# ATSAMD20G16B device description
Architecture: CORTEX-M0PLUS; Family: SAMD; Series: SAMD20
Registers are 8-bit, read-write, reset 0x0 unless marked. A register's access mark holds for its fields unless they carry their own. Offsets are from the block's base; [hi:lo] are bit positions; lines under a group give offsets from that group; {n}, {i} and the like mark numbered series; 'fields as' and 'values as' point back to an identical list.

## PAC — Peripheral Access Controller
Instances: PAC0 0x40000000, PAC1 0x41000000, PAC2 0x42000000
0x00 WPCLR 32-bit (atomic clear) — Write Protection Clear
  [31:1] WP
0x04 WPSET 32-bit (atomic set) — Write Protection Set
  [31:1] WP

## PM — Power Manager
Instances: PM 0x40000400
0x00 CTRL — Control
0x01 SLEEP — Sleep Mode
  [1:0] IDLE — Idle Mode Configuration
    0=CPU (The CPU clock domain is stopped); 1=AHB (The CPU and AHB clock domains are stopped); 2=APB (The CPU, AHB and APB clock domains are stopped)
0x08 CPUSEL — CPU Clock Select
  [2:0] CPUDIV — CPU Prescaler Selection
    0=DIV1 (Divide by 1); 1=DIV2 (Divide by 2); 2=DIV4 (Divide by 4); 3=DIV8 (Divide by 8); 4=DIV16 (Divide by 16); 5=DIV32 (Divide by 32); 6=DIV64 (Divide by 64); 7=DIV128 (Divide by 128)
0x09 APBASEL — APBA Clock Select
  [2:0] APBADIV — APBA Prescaler Selection
    values as CPUSEL.CPUDIV
0x0A APBBSEL — APBB Clock Select
  [2:0] APBBDIV — APBB Prescaler Selection
    values as CPUSEL.CPUDIV
0x0B APBCSEL — APBC Clock Select
  [2:0] APBCDIV — APBC Prescaler Selection
    values as CPUSEL.CPUDIV
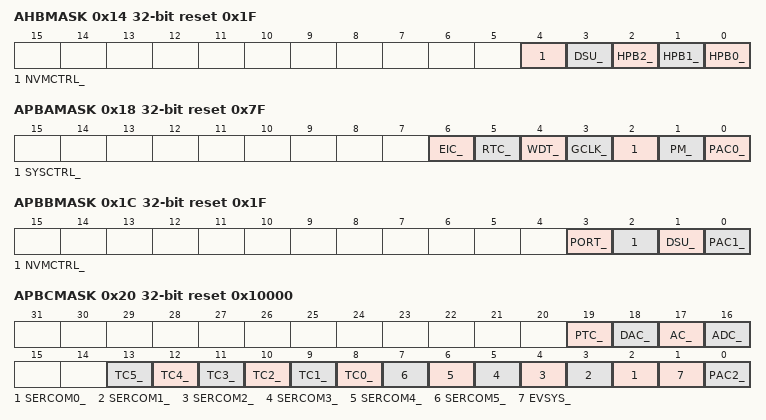
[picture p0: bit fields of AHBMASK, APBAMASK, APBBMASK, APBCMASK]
0x14 AHBMASK 32-bit reset 0x1F
  [4] NVMCTRL_ — NVMCTRL AHB Clock Mask
  [3] DSU_ — DSU AHB Clock Mask
  [2] HPB2_ — HPB2 AHB Clock Mask
  [1] HPB1_ — HPB1 AHB Clock Mask
  [0] HPB0_ — HPB0 AHB Clock Mask
0x18 APBAMASK 32-bit reset 0x7F
  [6] EIC_ — EIC APB Clock Enable
  [5] RTC_ — RTC APB Clock Enable
  [4] WDT_ — WDT APB Clock Enable
  [3] GCLK_ — GCLK APB Clock Enable
  [2] SYSCTRL_ — SYSCTRL APB Clock Enable
  [1] PM_ — PM APB Clock Enable
  [0] PAC0_ — PAC0 APB Clock Enable
0x1C APBBMASK 32-bit reset 0x1F
  [3] PORT_ — PORT APB Clock Enable
  [2] NVMCTRL_ — NVMCTRL APB Clock Enable
  [1] DSU_ — DSU APB Clock Enable
  [0] PAC1_ — PAC1 APB Clock Enable
0x20 APBCMASK 32-bit reset 0x10000
  [19] PTC_ — PTC APB Clock Enable
  [18] DAC_ — DAC APB Clock Enable
  [17] AC_ — AC APB Clock Enable
  [16] ADC_ — ADC APB Clock Enable
  [n+8] TC{n}_ (n=0..5) — TC{n} APB Clock Enable
  [n+2] SERCOM{n}_ (n=0..5) — SERCOM{n} APB Clock Enable
  [1] EVSYS_ — EVSYS APB Clock Enable
  [0] PAC2_ — PAC2 APB Clock Enable
0x34 INTENCLR (atomic clear) — Interrupt Enable Clear
  [0] CKRDY — Clock Ready Interrupt Enable
0x35 INTENSET (atomic set) — Interrupt Enable Set
  [0] CKRDY — Clock Ready Interrupt Enable
0x36 INTFLAG (atomic clear) — Interrupt Flag Status and Clear
  [0] CKRDY — Clock Ready
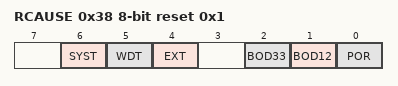
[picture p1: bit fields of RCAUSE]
0x38 RCAUSE ro reset 0x1 — Reset Cause
  [6] SYST — System Reset Request
  [5] WDT — Watchdog Reset
  [4] EXT — External Reset
  [2] BOD33 — Brown Out 33 Detector Reset
  [1] BOD12 — Brown Out 12 Detector Reset
  [0] POR — Power On Reset

## PORT — Port Module
Instances: PORT 0x41004400, PORT_IOBUS 0x60000000
{0x0+0x80*i} GROUP[{i}] (i=0..1) group
  0x00 DIR 32-bit — Data Direction
    [31:0] DIR — Port Data Direction
  0x04 DIRCLR 32-bit (atomic clear of DIR) — Data Direction Clear
    [31:0] DIRCLR — Port Data Direction Clear
  0x08 DIRSET 32-bit (atomic set of DIR) — Data Direction Set
    [31:0] DIRSET — Port Data Direction Set
  0x0C DIRTGL 32-bit (atomic toggle of DIR) — Data Direction Toggle
    [31:0] DIRTGL — Port Data Direction Toggle
  0x10 OUT 32-bit — Data Output Value
    [31:0] OUT — Port Data Output Value
  0x14 OUTCLR 32-bit (atomic clear of OUT) — Data Output Value Clear
    [31:0] OUTCLR — Port Data Output Value Clear
  0x18 OUTSET 32-bit (atomic set of OUT) — Data Output Value Set
    [31:0] OUTSET — Port Data Output Value Set
  0x1C OUTTGL 32-bit (atomic toggle of OUT) — Data Output Value Toggle
    [31:0] OUTTGL — Port Data Output Value Toggle
  0x20 IN 32-bit ro — Data Input Value
    [31:0] IN — Port Data Input Value
  0x24 CTRL 32-bit — Control
    [31:0] SAMPLING — Input Sampling Mode
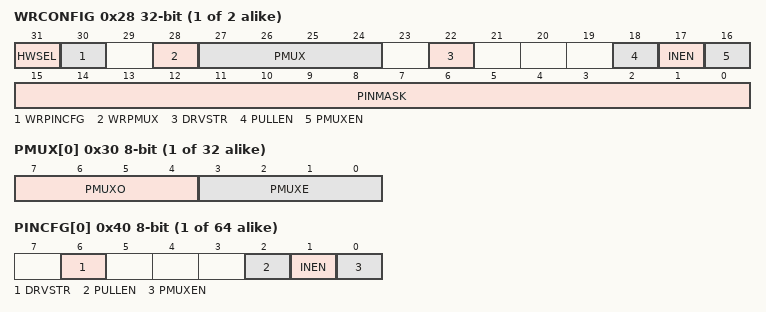
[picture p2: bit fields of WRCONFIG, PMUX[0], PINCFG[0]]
  0x28 WRCONFIG 32-bit wo — Write Configuration
    [31] HWSEL — Half-Word Select
    [30] WRPINCFG — Write PINCFG
    [28] WRPMUX — Write PMUX
    [27:24] PMUX — Peripheral Multiplexing
    [22] DRVSTR — Output Driver Strength Selection
    [18] PULLEN — Pull Enable
    [17] INEN — Input Enable
    [16] PMUXEN — Peripheral Multiplexer Enable
    [15:0] PINMASK — Pin Mask for Multiple Pin Configuration
  {0x30+j} PMUX[{j}] (j=0..15) — Peripheral Multiplexing n
    [7:4] PMUXO — Peripheral Multiplexing Odd
      0=A (Peripheral function A selected); 1=B (Peripheral function B selected); 2=C (Peripheral function C selected); 3=D (Peripheral function D selected); 4=E (Peripheral function E selected); 5=F (Peripheral function F selected); 6=G (Peripheral function G selected); 7=H (Peripheral function H selected)
    [3:0] PMUXE — Peripheral Multiplexing Even
      values as PMUXO
  {0x40+j} PINCFG[{j}] (j=0..31) — Pin Configuration n
    [6] DRVSTR — Output Driver Strength Selection
    [2] PULLEN — Pull Enable
    [1] INEN — Input Enable
    [0] PMUXEN — Peripheral Multiplexer Enable
